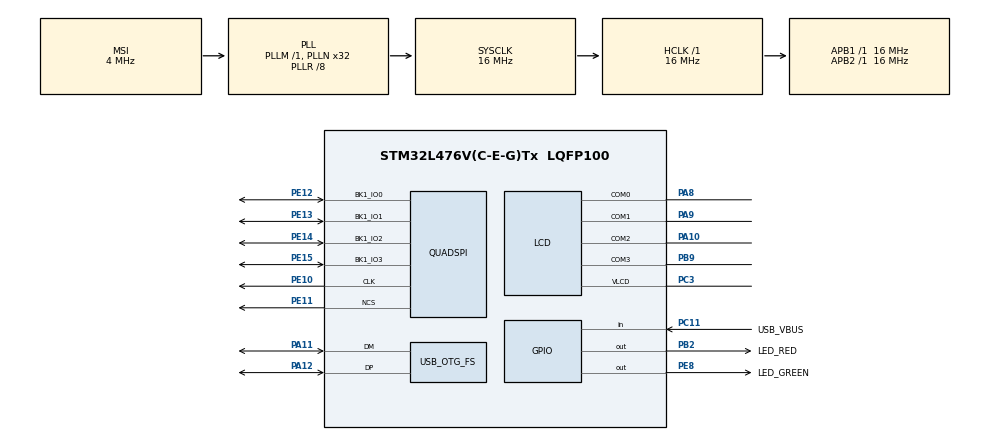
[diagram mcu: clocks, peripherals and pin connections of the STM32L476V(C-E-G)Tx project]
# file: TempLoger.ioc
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Mcu.Family=STM32L4
Mcu.Name=STM32L476V(C-E-G)Tx
Mcu.Package=LQFP100
NVIC.OTG_FS_IRQn=true\:0\:0\:false\:false\:true\:false\:true\:true
NVIC.PriorityGroup=NVIC_PRIORITYGROUP_4
PA10.Mode=1/4 Duty Cycle
PA10.Signal=LCD_COM2
PA11.Mode=Device_Only
PA11.Signal=USB_OTG_FS_DM
PA12.Mode=Device_Only
PA12.Signal=USB_OTG_FS_DP
PA13\ (JTMS-SWDIO).Mode=Serial_Wire
PA13\ (JTMS-SWDIO).Signal=SYS_JTMS-SWDIO
PA14\ (JTCK-SWCLK).Mode=Serial_Wire
PA14\ (JTCK-SWCLK).Signal=SYS_JTCK-SWCLK
PA8.Mode=1/4 Duty Cycle
PA8.Signal=LCD_COM0
PA9.Mode=1/4 Duty Cycle
PA9.Signal=LCD_COM1
PB2.GPIO_Label=LED_RED
PB2.Signal=GPIO_Output
PB9.Mode=1/4 Duty Cycle
PB9.Signal=LCD_COM3
PC11.GPIO_Label=USB_VBUS
PC11.Signal=GPIO_Input
PC14-OSC32_IN\ (PC14).Mode=LSE-External-Oscillator
PC14-OSC32_IN\ (PC14).Signal=RCC_OSC32_IN
PC15-OSC32_OUT\ (PC15).Mode=LSE-External-Oscillator
PC15-OSC32_OUT\ (PC15).Signal=RCC_OSC32_OUT
PC3.Mode=1/4 Duty Cycle
PC3.Signal=LCD_VLCD
PE10.Mode=Single Bank
PE10.Signal=QUADSPI_CLK
PE11.Mode=Single Bank
PE11.Signal=QUADSPI_NCS
PE12.Mode=Single Bank
PE12.Signal=QUADSPI_BK1_IO0
PE13.Mode=Single Bank
PE13.Signal=QUADSPI_BK1_IO1
PE14.Mode=Single Bank
PE14.Signal=QUADSPI_BK1_IO2
PE15.Mode=Single Bank
PE15.Signal=QUADSPI_BK1_IO3
PE8.GPIO_Label=LED_GREEN
PE8.Signal=GPIO_Output
ProjectManager.HeapSize=0x200
ProjectManager.StackSize=0x400
ProjectManager.TargetToolchain=MDK-ARM V5.32
QUADSPI.ClockPrescaler-Single\ Bank=0
QUADSPI.FifoThreshold-Single\ Bank=4
QUADSPI.FlashSize-Single\ Bank=17
RCC.ADCFreq_Value=96000000
RCC.AHBFreq_Value=16000000
RCC.APB1Freq_Value=16000000
RCC.APB1TimFreq_Value=16000000
RCC.APB2Freq_Value=16000000
RCC.APB2TimFreq_Value=16000000
RCC.CortexFreq_Value=16000000
RCC.HCLKFreq_Value=16000000
RCC.HSE_VALUE=8000000
RCC.HSI_VALUE=16000000
RCC.MSI_VALUE=4000000
RCC.PLLN=32
RCC.PLLR=RCC_PLLR_DIV8
RCC.PLLSAI1N=48
RCC.PLLSAI1Q=RCC_PLLQ_DIV4
RCC.SYSCLKFreq_VALUE=16000000
RCC.SYSCLKSource=RCC_SYSCLKSOURCE_PLLCLK
RCC.USBFreq_Value=48000000
RCC.VCOOutputFreq_Value=128000000
USB_DEVICE.CLASS_NAME_FS=MSC
USB_DEVICE.MSC_MEDIA_PACKET=4096
USB_DEVICE.USBD_LPM_ENABLED=0
USB_DEVICE.VirtualMode=Msc
USB_DEVICE.VirtualModeFS=Msc_FS
USB_OTG_FS.VirtualMode=Device_Only
VP_USB_DEVICE_VS_USB_DEVICE_MSC_FS.Mode=MSC_FS
board=custom

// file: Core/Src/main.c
/* USER CODE BEGIN Header */
/**
  ******************************************************************************
  * @file           : main.c
  * @brief          : Main program body
  ******************************************************************************
  * @attention
  *
  * Copyright (c) 2025 STMicroelectronics.
  * All rights reserved.
  *
  * This software is licensed under terms that can be found in the LICENSE file
  * in the root directory of this software component.
  * If no LICENSE file comes with this software, it is provided AS-IS.
  *
  ******************************************************************************
  */
/* USER CODE END Header */
#include "main.h"
#include "lcd.h"
#include "quadspi.h"
#include "usb_device.h"
#include "gpio.h"

/* USER CODE BEGIN Includes */
#include "loggerAppl.h"
/* USER CODE END Includes */

void SystemClock_Config(void);

int main(void)
{

  /* MCU Configuration--------------------------------------------------------*/

  /* Reset of all peripherals, Initializes the Flash interface and the Systick. */
  HAL_Init();

  /* Configure the system clock */
  SystemClock_Config();

  /* Initialize all configured peripherals */
  MX_GPIO_Init();
  MX_LCD_Init();
  MX_QUADSPI_Init();
  MX_USB_DEVICE_Init();

  /* Infinite loop */
  /* USER CODE BEGIN WHILE */
  while (1)
  {
    loggerAppl_start();
    /* USER CODE END WHILE */

  }
}

void SystemClock_Config(void)
{
  RCC_OscInitTypeDef RCC_OscInitStruct = {0};
  RCC_ClkInitTypeDef RCC_ClkInitStruct = {0};

  /** Configure the main internal regulator output voltage
  */
  if (HAL_PWREx_ControlVoltageScaling(PWR_REGULATOR_VOLTAGE_SCALE1) != HAL_OK)
  {
    Error_Handler();
  }

  /** Configure LSE Drive Capability
  */
  HAL_PWR_EnableBkUpAccess();
  __HAL_RCC_LSEDRIVE_CONFIG(RCC_LSEDRIVE_LOW);

  /** Initializes the RCC Oscillators according to the specified parameters
  * in the RCC_OscInitTypeDef structure.
  */
  RCC_OscInitStruct.OscillatorType = RCC_OSCILLATORTYPE_LSI|RCC_OSCILLATORTYPE_LSE
                              |RCC_OSCILLATORTYPE_MSI;
  RCC_OscInitStruct.LSEState = RCC_LSE_ON;
  RCC_OscInitStruct.LSIState = RCC_LSI_ON;
  RCC_OscInitStruct.MSIState = RCC_MSI_ON;
  RCC_OscInitStruct.MSICalibrationValue = 0;
  RCC_OscInitStruct.MSIClockRange = RCC_MSIRANGE_6;
  RCC_OscInitStruct.PLL.PLLState = RCC_PLL_ON;
  RCC_OscInitStruct.PLL.PLLSource = RCC_PLLSOURCE_MSI;
  RCC_OscInitStruct.PLL.PLLM = 1;
  RCC_OscInitStruct.PLL.PLLN = 32;
  RCC_OscInitStruct.PLL.PLLP = RCC_PLLP_DIV7;
  RCC_OscInitStruct.PLL.PLLQ = RCC_PLLQ_DIV2;
  RCC_OscInitStruct.PLL.PLLR = RCC_PLLR_DIV8;
  if (HAL_RCC_OscConfig(&RCC_OscInitStruct) != HAL_OK)
  {
    Error_Handler();
  }

  /** Initializes the CPU, AHB and APB buses clocks
  */
  RCC_ClkInitStruct.ClockType = RCC_CLOCKTYPE_HCLK|RCC_CLOCKTYPE_SYSCLK
                              |RCC_CLOCKTYPE_PCLK1|RCC_CLOCKTYPE_PCLK2;
  RCC_ClkInitStruct.SYSCLKSource = RCC_SYSCLKSOURCE_PLLCLK;
  RCC_ClkInitStruct.AHBCLKDivider = RCC_SYSCLK_DIV1;
  RCC_ClkInitStruct.APB1CLKDivider = RCC_HCLK_DIV1;
  RCC_ClkInitStruct.APB2CLKDivider = RCC_HCLK_DIV1;

  if (HAL_RCC_ClockConfig(&RCC_ClkInitStruct, FLASH_LATENCY_0) != HAL_OK)
  {
    Error_Handler();
  }

  /** Enable MSI Auto calibration
  */
  HAL_RCCEx_EnableMSIPLLMode();
}

void Error_Handler(void)
{
  __disable_irq();
  while (1)
  {
  }
}
